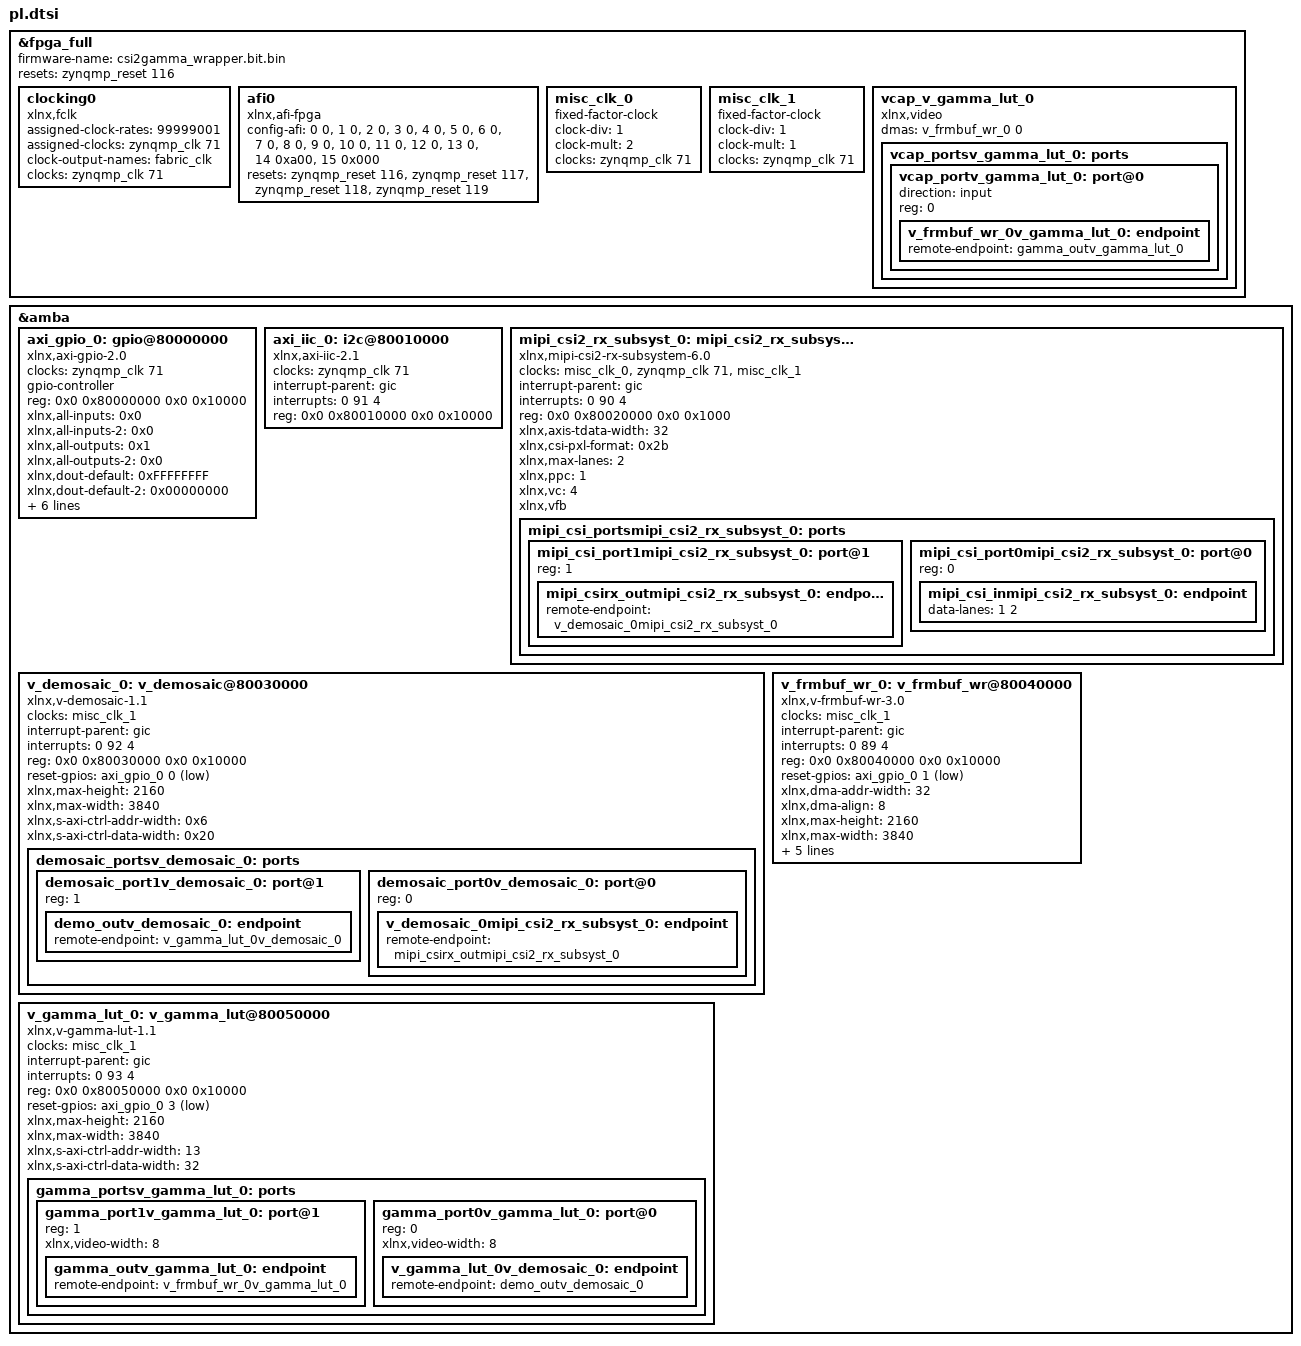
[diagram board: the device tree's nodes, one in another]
/*
 * CAUTION: This file is automatically generated by Xilinx.
 * Version: XSCT 2025.1
 * Today is: Wed Sep  2 19:42:46 2026
 */


/dts-v1/;
/plugin/;
&fpga_full {
	firmware-name = "csi2gamma_wrapper.bit.bin";
	resets = <&zynqmp_reset 116>;
	clocking0: clocking0 {
		#clock-cells = <0>;
		assigned-clock-rates = <99999001>;
		assigned-clocks = <&zynqmp_clk 71>;
		clock-output-names = "fabric_clk";
		clocks = <&zynqmp_clk 71>;
		compatible = "xlnx,fclk";
	};
	afi0: afi0 {
		compatible = "xlnx,afi-fpga";
		config-afi = < 0 0>, <1 0>, <2 0>, <3 0>, <4 0>, <5 0>, <6 0>, <7 0>, <8 0>, <9 0>, <10 0>, <11 0>, <12 0>, <13 0>, <14 0xa00>, <15 0x000>;
		resets = <&zynqmp_reset 116>, <&zynqmp_reset 117>, <&zynqmp_reset 118>, <&zynqmp_reset 119>;
	};
	misc_clk_0: misc_clk_0 {
		#clock-cells = <0>;
		clock-div = <1>;
		clock-mult = <2>;
		clocks = <&zynqmp_clk 71>;
		compatible = "fixed-factor-clock";
	};
	misc_clk_1: misc_clk_1 {
		#clock-cells = <0>;
		clock-div = <1>;
		clock-mult = <1>;
		clocks = <&zynqmp_clk 71>;
		compatible = "fixed-factor-clock";
	};
	vcap_v_gamma_lut_0 {
		compatible = "xlnx,video";
		dma-names = "port0";
		dmas = <&v_frmbuf_wr_0 0>;
		vcap_portsv_gamma_lut_0: ports {
			#address-cells = <1>;
			#size-cells = <0>;
			vcap_portv_gamma_lut_0: port@0 {
				direction = "input";
				reg = <0>;
				v_frmbuf_wr_0v_gamma_lut_0: endpoint {
					remote-endpoint = <&gamma_outv_gamma_lut_0>;
				};
			};
		};
	};
};
&amba {
	#address-cells = <2>;
	#size-cells = <2>;
	axi_gpio_0: gpio@80000000 {
		#gpio-cells = <2>;
		clock-names = "s_axi_aclk";
		clocks = <&zynqmp_clk 71>;
		compatible = "xlnx,axi-gpio-2.0", "xlnx,xps-gpio-1.00.a";
		gpio-controller ;
		reg = <0x0 0x80000000 0x0 0x10000>;
		xlnx,all-inputs = <0x0>;
		xlnx,all-inputs-2 = <0x0>;
		xlnx,all-outputs = <0x1>;
		xlnx,all-outputs-2 = <0x0>;
		xlnx,dout-default = <0xFFFFFFFF>;
		xlnx,dout-default-2 = <0x00000000>;
		xlnx,gpio-width = <0x5>;
		xlnx,gpio2-width = <0x20>;
		xlnx,interrupt-present = <0x0>;
		xlnx,is-dual = <0x0>;
		xlnx,tri-default = <0xFFFFFFFF>;
		xlnx,tri-default-2 = <0xFFFFFFFF>;
	};
	axi_iic_0: i2c@80010000 {
		#address-cells = <1>;
		#size-cells = <0>;
		clock-names = "s_axi_aclk";
		clocks = <&zynqmp_clk 71>;
		compatible = "xlnx,axi-iic-2.1", "xlnx,xps-iic-2.00.a";
		interrupt-names = "iic2intc_irpt";
		interrupt-parent = <&gic>;
		interrupts = <0 91 4>;
		reg = <0x0 0x80010000 0x0 0x10000>;
	};
	mipi_csi2_rx_subsyst_0: mipi_csi2_rx_subsystem@80020000 {
		clock-names = "dphy_clk_200M", "lite_aclk", "video_aclk";
		clocks = <&misc_clk_0>, <&zynqmp_clk 71>, <&misc_clk_1>;
		compatible = "xlnx,mipi-csi2-rx-subsystem-6.0", "xlnx,mipi-csi2-rx-subsystem-5.0";
		interrupt-names = "csirxss_csi_irq";
		interrupt-parent = <&gic>;
		interrupts = <0 90 4>;
		reg = <0x0 0x80020000 0x0 0x1000>;
		xlnx,axis-tdata-width = <32>;
		xlnx,csi-pxl-format = <0x2b>;
		xlnx,max-lanes = <2>;
		xlnx,ppc = <1>;
		xlnx,vc = <4>;
		xlnx,vfb ;
		mipi_csi_portsmipi_csi2_rx_subsyst_0: ports {
			#address-cells = <1>;
			#size-cells = <0>;
			mipi_csi_port1mipi_csi2_rx_subsyst_0: port@1 {
				reg = <1>;
				mipi_csirx_outmipi_csi2_rx_subsyst_0: endpoint {
					remote-endpoint = <&v_demosaic_0mipi_csi2_rx_subsyst_0>;
				};
			};
			mipi_csi_port0mipi_csi2_rx_subsyst_0: port@0 {
				/* User need to add something like remote-endpoint=<&out> under the node csiss_in:endpoint */
				reg = <0>;
				mipi_csi_inmipi_csi2_rx_subsyst_0: endpoint {
					data-lanes = <1 2>;
				};
			};
		};
	};
	v_demosaic_0: v_demosaic@80030000 {
		clock-names = "ap_clk";
		clocks = <&misc_clk_1>;
		compatible = "xlnx,v-demosaic-1.1", "xlnx,v-demosaic";
		interrupt-names = "interrupt";
		interrupt-parent = <&gic>;
		interrupts = <0 92 4>;
		reg = <0x0 0x80030000 0x0 0x10000>;
		reset-gpios = <&axi_gpio_0 0 1>;
		xlnx,max-height = <2160>;
		xlnx,max-width = <3840>;
		xlnx,s-axi-ctrl-addr-width = <0x6>;
		xlnx,s-axi-ctrl-data-width = <0x20>;
		demosaic_portsv_demosaic_0: ports {
			#address-cells = <1>;
			#size-cells = <0>;
			demosaic_port1v_demosaic_0: port@1 {
				reg = <1>;
				demo_outv_demosaic_0: endpoint {
					remote-endpoint = <&v_gamma_lut_0v_demosaic_0>;
				};
			};
			demosaic_port0v_demosaic_0: port@0 {
				reg = <0>;
				v_demosaic_0mipi_csi2_rx_subsyst_0: endpoint {
					remote-endpoint = <&mipi_csirx_outmipi_csi2_rx_subsyst_0>;
				};
			};
		};
	};
	v_frmbuf_wr_0: v_frmbuf_wr@80040000 {
		#dma-cells = <1>;
		clock-names = "ap_clk";
		clocks = <&misc_clk_1>;
		compatible = "xlnx,v-frmbuf-wr-3.0", "xlnx,axi-frmbuf-wr-v2.2";
		interrupt-names = "interrupt";
		interrupt-parent = <&gic>;
		interrupts = <0 89 4>;
		reg = <0x0 0x80040000 0x0 0x10000>;
		reset-gpios = <&axi_gpio_0 1 1>;
		xlnx,dma-addr-width = <32>;
		xlnx,dma-align = <8>;
		xlnx,max-height = <2160>;
		xlnx,max-width = <3840>;
		xlnx,pixels-per-clock = <1>;
		xlnx,s-axi-ctrl-addr-width = <0x7>;
		xlnx,s-axi-ctrl-data-width = <0x20>;
		xlnx,vid-formats = "rgb888", "bgr888";
		xlnx,video-width = <8>;
	};
	v_gamma_lut_0: v_gamma_lut@80050000 {
		clock-names = "ap_clk";
		clocks = <&misc_clk_1>;
		compatible = "xlnx,v-gamma-lut-1.1", "xlnx,v-gamma-lut";
		interrupt-names = "interrupt";
		interrupt-parent = <&gic>;
		interrupts = <0 93 4>;
		reg = <0x0 0x80050000 0x0 0x10000>;
		reset-gpios = <&axi_gpio_0 3 1>;
		xlnx,max-height = <2160>;
		xlnx,max-width = <3840>;
		xlnx,s-axi-ctrl-addr-width = <13>;
		xlnx,s-axi-ctrl-data-width = <32>;
		gamma_portsv_gamma_lut_0: ports {
			#address-cells = <1>;
			#size-cells = <0>;
			gamma_port1v_gamma_lut_0: port@1 {
				reg = <1>;
				xlnx,video-width = <8>;
				gamma_outv_gamma_lut_0: endpoint {
					remote-endpoint = <&v_frmbuf_wr_0v_gamma_lut_0>;
				};
			};
			gamma_port0v_gamma_lut_0: port@0 {
				reg = <0>;
				xlnx,video-width = <8>;
				v_gamma_lut_0v_demosaic_0: endpoint {
					remote-endpoint = <&demo_outv_demosaic_0>;
				};
			};
		};
	};
};
